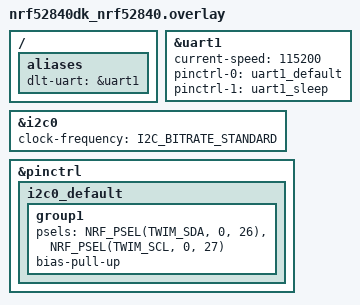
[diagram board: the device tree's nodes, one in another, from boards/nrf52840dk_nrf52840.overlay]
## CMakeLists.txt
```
# SPDX-License-Identifier: Apache-2.0

cmake_minimum_required(VERSION 3.20.0)
find_package(Zephyr REQUIRED HINTS $ENV{ZEPHYR_BASE})
project(base)

list(APPEND CMAKE_MODULE_PATH ${ZEPHYR_BASE}/modules/nanopb)
include(nanopb)

zephyr_nanopb_sources(app ${CMAKE_CURRENT_SOURCE_DIR}/../../../shared/phaethon.proto)

FILE(GLOB app_sources src/*.c)
FILE(GLOB lib_sources ../../lib/*.c)
target_sources(app PRIVATE ${app_sources} ${lib_sources})
target_include_directories(app PRIVATE ../../include)
```

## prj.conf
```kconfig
# GPIO Drivers
CONFIG_GPIO=y

# Shell Drivers
CONFIG_SHELL=y
CONFIG_SHELL_LOG_BACKEND=y
CONFIG_SHELL_ASYNC_API=y
CONFIG_SHELL_BACKEND_RTT=y

# Log Drivers
CONFIG_LOG=y
CONFIG_LOG_SPEED=y
CONFIG_LOG_CMDS=y
CONFIG_LOG_RUNTIME_FILTERING=y
CONFIG_LOG_BUFFER_SIZE=2048
CONFIG_LOG_PRINTK=y

# UART Drivers (DMA-based)
CONFIG_SERIAL=y
CONFIG_UART_ASYNC_API=y
CONFIG_UART_1_ASYNC=y

# Bluetooth
CONFIG_BT=y
CONFIG_BT_OBSERVER=y
CONFIG_BT_PERIPHERAL=y
CONFIG_BT_ZEPHYR_NUS=y
#CONFIG_BT_EXT_ADV=y
CONFIG_BT_FILTER_ACCEPT_LIST=y
CONFIG_BT_SHELL=y

# L2CAP SDU/PDU TX MTU
CONFIG_BT_BUF_ACL_TX_SIZE=251
CONFIG_BT_BUF_ACL_RX_SIZE=251
CONFIG_BT_L2CAP_TX_MTU=247

CONFIG_CBPRINTF_FP_SUPPORT=y

CONFIG_NANOPB=y

# FLYNN GPS i2C CONF
CONFIG_I2C=y
```

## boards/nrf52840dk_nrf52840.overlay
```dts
/ {
	aliases {
		dlt-uart = &uart1;
	};
};

&uart1 {
	status = "okay";
	current-speed = <115200>;
	pinctrl-0 = <&uart1_default>;
	pinctrl-1 = <&uart1_sleep>;
	pinctrl-names = "default", "sleep";
};

&i2c0 {
    clock-frequency = <I2C_BITRATE_STANDARD>;
};

&pinctrl {
    i2c0_default: i2c0_default {
		group1 {
			psels = <NRF_PSEL(TWIM_SDA, 0, 26)>,
				<NRF_PSEL(TWIM_SCL, 0, 27)>;
            bias-pull-up;
		};
	};
};
```

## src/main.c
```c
#include "zephyr/logging/log_core.h"
#include <math.h>
#include <zephyr/kernel.h>
#include <zephyr/drivers/gpio.h>
#include <zephyr/drivers/uart.h>
#include <zephyr/logging/log.h>
#include <pb_encode.h>
#include <pb_decode.h>

#ifdef CONFIG_SHELL_BACKEND_RTT
#include <zephyr/shell/shell_rtt.h>
#else
#include <zephyr/shell/shell.h>
#endif

#include "dlt_api.h"
#include "dlt_endpoints.h"
#include "base_bt.h"
#include "base_gps.h"
#include "phaethon.pb.h"

LOG_MODULE_REGISTER(base_main, LOG_LEVEL_INF);

#define PI 3.14159265358979323846f

/* Filter window for compass */
#define BEARING_FILTER_APERTURE  30.f

// Convert degrees to radians
static inline float degrees_to_radians(float degrees)
{
    return degrees * PI / 180.0f;
}

// Convert radians to degrees
static inline float radians_to_degrees(float radians)
{
    return radians * 180.0f / PI;
}

// Calculate the bearing between two points using the rhumb line technique
static float calculate_rhumb_line_bearing(float lat1, float lon1, float lat2,
                                          float lon2)
{
    
    /* Precalculate repeated values */
    const static float PI_ON_4 = PI / 4.0f;
    const static float TWO_PI = 2.0f * PI;
    
    // Convert latitudes and longitudes from degrees to radians
    float phi1 = degrees_to_radians(lat1);
    float phi2 = degrees_to_radians(lat2);
    float lambda1 = degrees_to_radians(lon1);
    float lambda2 = degrees_to_radians(lon2);

    // Calculate the projected latitude difference (Δψ)
    float delta_psi = logf(tanf(PI_ON_4 + phi2 / 2.0f) / tanf(PI_ON_4 + phi1 / 2.0f));

    // Calculate the difference in longitudes (Δλ)
    float delta_lambda = lambda2 - lambda1;

    // Adjust the difference in longitudes (Δλ) if necessary
    if (fabsf(delta_lambda) > PI) {
        if (delta_lambda > 0) {
            delta_lambda = -(TWO_PI - delta_lambda);
        } else {
            delta_lambda = TWO_PI + delta_lambda;
        }
    }

    // Calculate the bearing (brng)
    float bearing = atan2f(delta_lambda, delta_psi);

    // Convert the bearing from radians to degrees
    bearing = radians_to_degrees(bearing);

    // Normalize the bearing to be within the range [0, 360) degrees
    if (bearing < 0) {
        bearing += 360.0f;
    }

    return bearing;
}

// Check if the calculated bearing is within 30 degrees of the reference bearing
static bool is_within_bearing(float calculated_bearing, float reference_bearing) {
    float difference = fabsf(calculated_bearing - reference_bearing);

    // Adjust the difference to be the smallest angle between the bearings
    if (difference > 180.0f) {
        difference = 360.0f - difference;
    }

    // Return true if the difference is within 30 degrees
    return difference <= BEARING_FILTER_APERTURE;
}

int main(void)
{
    k_tid_t device_tid = k_current_get();
    dlt_interface_init(2);
    dlt_device_register(device_tid);

    /* Connect to the Thingy52 */
    LOG_INF("Connecting to Thingy52");
#ifdef CONFIG_SHELL_BACKEND_RTT
    shell_execute_cmd(shell_backend_rtt_get_ptr(), "blecon -s c8:91:07:19:03:58");
#else
    shell_execute_cmd(shell_backend_uart_get_ptr(), "blecon -s c8:91:07:19:03:58");
#endif

    uint8_t rx_data[DLT_MAX_DATA_LEN] = {0};
    uint8_t tx_buf[DLT_MAX_DATA_LEN] = {0};
    uint8_t resp_len = 0;
    uint8_t msg_type = 0;

    wsu_data_packet wsu; 
    bool wsu_conn = false;

    gps_base_data gps;
    gps.good_data = false;

    while (true) {

        /* Check the PI UART Link for data */
        resp_len = dlt_read(PI_UART, &msg_type, rx_data, DLT_MAX_DATA_LEN,
                            K_NO_WAIT);
        if (resp_len) {

            /* Decode message */
            bool status;

            /* Allocate space for the decoded message. */
            ADSBData message = ADSBData_init_zero;

            /* Create a stream that reads from the buffer. */
            pb_istream_t stream = pb_istream_from_buffer(rx_data, resp_len);

            /* Now we are ready to decode the message. */
            status = pb_decode(&stream, ADSBData_fields, &message);

            /* Check for errors */
            if (status) {
                /* Print the data contained in the message. */
                LOG_INF("Got packet for hex: %s", (char *)message.hex);
                // LOG_INF("flight: %s", message.flight);
                // LOG_INF("lat: %f", (double)message.lat);
                // LOG_INF("lon: %f", (double)message.lon);
                // LOG_INF("alt: %d", message.altitude);
                // LOG_INF("speed: %d", message.speed);
                // LOG_INF("track: %d", message.track);
            } else {
                LOG_ERR("Decoding failed: %s\n", PB_GET_ERROR(&stream));
            }

            /* GPS not bad */
            if (gps.good_data) {
                /* Filter the message */
                float rhumb_bearing = calculate_rhumb_line_bearing(gps.latitude,
                                                                gps.longitude,
                                                                message.lat,
                                                                message.lon);

                bool allow = is_within_bearing(rhumb_bearing, wsu.yaw);
                if (allow && wsu_conn) {
                    /* Forward message */
                    LOG_INF("Forwarding packet to M5.");
                    dlt_request(M5_NUS, tx_buf, rx_data, resp_len, true);
                } else {
                    LOG_INF("Ignoring packet. Not in heading.");
                }
            }
        }

        /* Check IMU data */
        if (!base_bt_wsu_data_recv(&wsu, K_NO_WAIT)) {
            /* Print the packet */
            // LOG_INF("p %f, r %f, y %f", (double)wsu.pitch,
            //         (double)wsu.roll, (double)wsu.yaw);
            LOG_INF("Yaw: %.02f", (double)wsu.yaw);
            wsu_conn = true;
        }

        /* Check GPS data */
        if (!base_gps_i2c_data_recv(&gps, K_NO_WAIT)) {
                if (gps.good_data) {
                    LOG_INF("lat: %f, lon %f", (double)gps.latitude, (double)gps.longitude);
                } else {
                    LOG_INF("GPS data is bad.");
                }
        }

        k_sleep(K_MSEC(3));
    }

    return 0;
}
```

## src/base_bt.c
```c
#include "zephyr/bluetooth/addr.h"
#include "zephyr/bluetooth/gap.h"
#include <zephyr/bluetooth/bluetooth.h>
#include <zephyr/kernel.h>
#include <zephyr/logging/log.h>

#include "base_bt.h"

LOG_MODULE_REGISTER(base_bt_module, LOG_LEVEL_ERR);

/* Thread parameters */
#define T_BASE_BT_STACKSIZE 1024
#define T_BASE_BT_PRIORITY  7

/* BASE BT State Machine States */
#define BASE_BT_IDLE_STATE      0
#define BASE_BT_SCANNING_STATE  1
#define BASE_BT_CONNECTED_STATE 2

/* Indexes into bt_data::data */
#define WSU_BT_DATA_MAJOR_START_IDX 20 // EXT implementation
#define WSU_BT_DATA_SEQ_START_IDX   10 
#define WSU_BT_DATA_PITCH_START_IDX 12 
#define WSU_BT_DATA_ROLL_START_IDX  16
#define WSU_BT_DATA_YAW_START_IDX   20

/* Define the message queue BT state machine commands */
K_MSGQ_DEFINE(base_bt_cmdq, sizeof(base_bt_cmd_t), 2, 1);

/* Define the message queue for passing WSU data */
K_MSGQ_DEFINE(wsu_dataq, sizeof(wsu_data_packet), 10, 1);

/* BASE BT State variable */
static uint8_t base_bt_state = BASE_BT_IDLE_STATE;

/* Rate limiting variables for HCI data forwarding */
uint64_t last_device_tx[4] = {0};

/* Send a cmd via the cmd queue */
extern void base_bt_cmd_send(base_bt_cmd_t *cmd, k_timeout_t timeout)
{
    k_msgq_put(&base_bt_cmdq, cmd, timeout);
}

/* Receive a message from the cmd queue */
static inline int base_bt_cmd_recv(base_bt_cmd_t *cmd, k_timeout_t timeout)
{
    return k_msgq_get(&base_bt_cmdq, cmd, timeout);
}

/* Send a cmd via the cmd queue */
static inline void base_bt_wsu_data_send(wsu_data_packet *pkt, k_timeout_t timeout)
{
    k_msgq_put(&wsu_dataq, pkt, timeout);
}

/* Receive a message from the cmd queue */
extern int base_bt_wsu_data_recv(wsu_data_packet *pkt, k_timeout_t timeout)
{
    return k_msgq_get(&wsu_dataq, pkt, timeout);
}

/* Initialise Bluetooth */
static inline bool base_bt_init(void)
{
    int err = bt_enable(NULL);
    if (err) {
        LOG_ERR("Bluetooth init failed (err %d)\n", err);
        return false;
    }
    return true;
}


static bool conn_data_cb(struct bt_data *data, void *user_data)
{
    /* Ignore non-manufacturer data segments */
    if (data->type != BT_DATA_MANUFACTURER_DATA) {
        /* Move to the next segment */
        return true;
    }

    /* Type-pun the packet value */
    union {
        uint32_t  u;
        float     f;
    } packet;

    #ifdef CONFIG_BT_EXT_ADV
    packet.u = 0;
    packet.u |= data->data[WSU_BT_DATA_MAJOR_START_IDX + 3];
    packet.u |= (((uint32_t)data->data[WSU_BT_DATA_MAJOR_START_IDX + 2]) << 8);
    packet.u |= (((uint32_t)data->data[WSU_BT_DATA_MAJOR_START_IDX + 1]) << 16);
    packet.u |= (((uint32_t)data->data[WSU_BT_DATA_MAJOR_START_IDX]) << 24);

    wsu_data_packet *p = user_data;
    p->type = data->data[WSU_BT_DATA_MAJOR_START_IDX - 1];
    p->value = packet.f;

    /* Print the packet */
    if (p->type == 0x01) {
        LOG_INF("pitch: %f\n", (double)p->value);
    } else if (p->type == 0x02) {
        LOG_INF("roll: %f\n", (double)p->value);
    } else if (p->type == 0x03) {
        LOG_INF("yaw: %f\n", (double)p->value);
    }
    #else
    wsu_data_packet *p = user_data;

    /* Get sequence */
    p->sequence = (((uint16_t)data->data[WSU_BT_DATA_SEQ_START_IDX]) << 8);
    p->sequence |= data->data[WSU_BT_DATA_SEQ_START_IDX + 1];

    /* Get pitch */
    packet.u = 0;
    packet.u |= data->data[WSU_BT_DATA_PITCH_START_IDX + 3];
    packet.u |= (((uint32_t)data->data[WSU_BT_DATA_PITCH_START_IDX + 2]) << 8);
    packet.u |= (((uint32_t)data->data[WSU_BT_DATA_PITCH_START_IDX + 1]) << 16);
    packet.u |= (((uint32_t)data->data[WSU_BT_DATA_PITCH_START_IDX]) << 24);
    p->pitch = packet.f;

    /* Get roll */
    packet.u = 0;
    packet.u |= data->data[WSU_BT_DATA_ROLL_START_IDX + 3];
    packet.u |= (((uint32_t)data->data[WSU_BT_DATA_ROLL_START_IDX + 2]) << 8);
    packet.u |= (((uint32_t)data->data[WSU_BT_DATA_ROLL_START_IDX + 1]) << 16);
    packet.u |= (((uint32_t)data->data[WSU_BT_DATA_ROLL_START_IDX]) << 24);
    p->roll = packet.f;

    /* Get yaw */
    packet.u = 0;
    packet.u |= data->data[WSU_BT_DATA_YAW_START_IDX + 3];
    packet.u |= (((uint32_t)data->data[WSU_BT_DATA_YAW_START_IDX + 2]) << 8);
    packet.u |= (((uint32_t)data->data[WSU_BT_DATA_YAW_START_IDX + 1]) << 16);
    packet.u |= (((uint32_t)data->data[WSU_BT_DATA_YAW_START_IDX]) << 24);
    p->yaw = packet.f;

    /* Print the packet */
    LOG_INF("seq %" PRIu16 " p %f, r %f, y %f\n", p->sequence, (double)p->pitch,
            (double)p->roll, (double)p->yaw);
    #endif

    /* Stop data processing */
    return false;
}

/* Scan callback function for handling generic scanning */
static void ble_scan_recv(const bt_addr_le_t *addr, int8_t rssi, uint8_t type,
                          struct net_buf_simple *ad)
{
    if (base_bt_state != BASE_BT_SCANNING_STATE) {
        return;
    }
    char addr_str[BT_ADDR_LE_STR_LEN];
    bt_addr_le_to_str(addr, addr_str, sizeof(addr_str));
    printk("Device found: %s (RSSI %d), type %u, AD data len %u\n", addr_str,
           rssi, type, ad->len);
}

/* Scan callback function for handling WSU beacon connections */
static void ble_conn_recv(const bt_addr_le_t *addr, int8_t rssi, uint8_t type,
                          struct net_buf_simple *ad)
{
    if (base_bt_state != BASE_BT_CONNECTED_STATE) {
        return;
    }

    char addr_str[BT_ADDR_LE_STR_LEN];
    bt_addr_le_to_str(addr, addr_str, sizeof(addr_str));

    /* Parse the WSU data */
    wsu_data_packet packet;
    bt_data_parse(ad, conn_data_cb, &packet);
    
    /* Send it to the main thread */
    base_bt_wsu_data_send(&packet, K_MSEC(1));
    
}

/* State machine which bakes the Bluetooth API cmds into transition logic. */
void base_bt_thread(void)
{
    /* Initialise the module */
    // if (!base_bt_init()) {
    //     LOG_ERR("BASE BT init failed.");
    //     return;
    // }

    /* Set the scan parameters */
    struct bt_le_scan_param scan_param = {
        .type = BT_LE_SCAN_TYPE_PASSIVE,
        .options = BT_LE_SCAN_OPT_NONE,
        .interval = BT_GAP_SCAN_FAST_INTERVAL_MIN,
        .window = BT_GAP_SCAN_FAST_WINDOW
    };

    while (1) {
        base_bt_cmd_t cmd;
        int err;
        switch (base_bt_state) {
        case BASE_BT_IDLE_STATE:
            /* Do nothing while waiting for a command */
            base_bt_cmd_recv(&cmd, K_FOREVER);

            /* Process the command */
            if (cmd.cmd_type == BASE_BT_SCAN_START && !cmd.filter) {
                /* Start the scan */
                scan_param.options = BT_LE_SCAN_OPT_FILTER_DUPLICATE;
                err = bt_le_scan_start(&scan_param, ble_scan_recv);
                if (err) {
                    LOG_ERR("Start SCAN failed (err %d)\n", err);
                    break;
                }

                LOG_INF("Transitioning to scanning state.");
                base_bt_state = BASE_BT_SCANNING_STATE;

            } else if (cmd.cmd_type == BASE_BT_SCAN_START && cmd.filter) {
                /* Setup the filter */
                bt_le_filter_accept_list_add(&cmd.addr);
                scan_param.options |= BT_LE_SCAN_OPT_FILTER_ACCEPT_LIST;

                /* Start the scan */
                err = bt_le_scan_start(&scan_param, ble_scan_recv);
                if (err) {
                    LOG_ERR("Start SCAN failed (err %d)\n", err);
                    break;
                }

                LOG_INF("Transitioning to scanning state (filtered).");
                base_bt_state = BASE_BT_SCANNING_STATE;

            } else if (cmd.cmd_type == BASE_BT_CONN_START) {
                /* Setup the filter */
                bt_le_filter_accept_list_add(&cmd.addr);
                scan_param.options |= BT_LE_SCAN_OPT_FILTER_ACCEPT_LIST;

                /* Start the scan */
                err = bt_le_scan_start(&scan_param, ble_conn_recv);
                if (err) {
                    LOG_ERR("Start CONN failed (err %d)\n", err);
                    break;
                }

                LOG_INF("Transitioning to connected state.");
                base_bt_state = BASE_BT_CONNECTED_STATE;

            } else {
                LOG_ERR("Invalid transition cmd from IDLE state.");
            }
            break;

        case BASE_BT_SCANNING_STATE:
            /* Do nothing while waiting for a command */
            base_bt_cmd_recv(&cmd, K_FOREVER);

            /* Only accept stop commands in the SCAN state*/
            if (cmd.cmd_type == BASE_BT_SCAN_STOP && !cmd.filter) {
                /* Stop scanning */
                err = bt_le_scan_stop();
                if (err) {
                    LOG_ERR("Stop SCAN failed (err %d)\n", err);
                    break;
                }

                /* Reset the filter list */
                bt_le_filter_accept_list_clear();

                LOG_INF("Transitioning to IDLE state.");
                base_bt_state = BASE_BT_IDLE_STATE;

            } else if (cmd.cmd_type == BASE_BT_SCAN_STOP && cmd.filter) {
                /* Stop the scan */
                err = bt_le_scan_stop();
                if (err) {
                    LOG_ERR("Stop SCAN failed (err %d)\n", err);
                    break;
                }

                /* Remove the address from the filter list */
                bt_le_filter_accept_list_remove(&cmd.addr);
                scan_param.options |= BT_LE_SCAN_OPT_FILTER_ACCEPT_LIST;

                /* Restart the scan */
                err = bt_le_scan_start(&scan_param, ble_scan_recv);
                if (err) {
                    LOG_ERR("Start SCAN failed (err %d)\n", err);
                    break;
                }

            } else if (cmd.cmd_type == BASE_BT_SCAN_START && cmd.filter) {
                /* Stop the scan */
                err = bt_le_scan_stop();
                if (err) {
                    LOG_ERR("Stop SCAN failed (err %d)\n", err);
                    break;
                }

                /* Add the new filter */
                bt_le_filter_accept_list_add(&cmd.addr);
                scan_param.options |= BT_LE_SCAN_OPT_FILTER_ACCEPT_LIST;

                /* Restart the scan */
                err = bt_le_scan_start(&scan_param, ble_scan_recv);
                if (err) {
                    LOG_ERR("Start SCAN failed (err %d)\n", err);
                    break;
                }

            } else if (cmd.cmd_type == BASE_BT_SCAN_START && !cmd.filter) {
                /* Stop the scan */
                err = bt_le_scan_stop();
                if (err) {
                    LOG_ERR("Stop SCAN failed (err %d)\n", err);
                    break;
                }

                /* Reset filter list and disable filtering */
                bt_le_filter_accept_list_clear();
                scan_param.options = BT_LE_SCAN_OPT_FILTER_DUPLICATE;
                ;

                /* Restart the scan */
                err = bt_le_scan_start(&scan_param, ble_scan_recv);
                if (err) {
                    LOG_ERR("Start SCAN failed (err %d)\n", err);
                    break;
                }

            } else {
                LOG_ERR("Invalid transition cmd from SCAN state.");
            }

            break;

        case BASE_BT_CONNECTED_STATE:
            /* Wait for a command */
            base_bt_cmd_recv(&cmd, K_FOREVER);

            if (cmd.cmd_type == BASE_BT_CONN_STOP) {

                /* Stop scanning and transition back to IDLE */
                err = bt_le_scan_stop();
                if (err) {
                    LOG_ERR("Stop SCAN failed (err %d)\n", err);
                    break;
                }

                /* Reset the filter list */
                bt_le_filter_accept_list_clear();

                LOG_INF("Transitioning to IDLE state.");
                base_bt_state = BASE_BT_IDLE_STATE;

            } else {
                LOG_ERR("Invalid transition cmd from CONN state.");
            }

            break;

        default:
            /* Shouldn't get here */
            base_bt_state = BASE_BT_IDLE_STATE;
            break;
        }
    }
}

K_THREAD_DEFINE(base_bt, T_BASE_BT_STACKSIZE, base_bt_thread, NULL, NULL, NULL,
                T_BASE_BT_PRIORITY, 0, 0);
```

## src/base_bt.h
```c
#ifndef BASE_BT_H_
#define BASE_BT_H_

#include <zephyr/bluetooth/addr.h>
#include <zephyr/kernel.h>

/* Command IDs for base_bt cmds */
#define BASE_BT_SCAN_START 0x00U
#define BASE_BT_SCAN_STOP  0x01U
#define BASE_BT_CONN_START 0x02U
#define BASE_BT_CONN_STOP  0x03U

#ifdef CONFIG_BT_EXT_ADV
typedef struct wsu_data_packet {
    uint8_t type;
    float value;
} wsu_data_packet;
#else
typedef struct wsu_data_packet {
    uint16_t sequence;
    float pitch;
    float roll;
    float yaw;
} wsu_data_packet;
#endif

/* base_bt_cmd_t represents commands to the ahu_bt state machine */
typedef struct {
    uint8_t cmd_type;
    bool filter;
    bt_addr_le_t addr;
} base_bt_cmd_t;

/* Prototypes */
extern void base_bt_cmd_send(base_bt_cmd_t *cmd, k_timeout_t timeout);
extern int base_bt_wsu_data_recv(wsu_data_packet *pkt, k_timeout_t timeout);

#endif
```

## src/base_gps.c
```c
/*
 * flynnmkelly
 */

#include <zephyr/kernel.h>
#include <zephyr/device.h>
#include <zephyr/drivers/uart.h>
#include <zephyr/drivers/i2c.h>
#include <zephyr/logging/log.h>
#include <string.h>
#include <stdio.h>
#include <stdlib.h>

#include "base_gps.h"

LOG_MODULE_REGISTER(gps_module, LOG_LEVEL_ERR);

/* Zephyr Handlers */
#define UART_DEVICE_NODE DT_CHOSEN(zephyr_shell_uart)
#define I2C_DEVICE_NODE DT_NODELABEL(i2c0) 

/* Thread Parameters */
#define T_BASE_GPS_STACKSIZE 2048 
#define T_BASE_GPS_PRIORITY  7

/* GPS i2C */
#define GPS_I2C_ADDR 0x10 // 7-bit unshifted default I2C Address
#define MAX_GPS_PACKET_SIZE 255
static uint8_t gps_data[MAX_GPS_PACKET_SIZE];

/* Config */
static const struct device *const uart_dev = DEVICE_DT_GET(UART_DEVICE_NODE);
static const struct device *i2c_dev;
uint32_t i2c_cfg = I2C_SPEED_SET(I2C_SPEED_STANDARD) | I2C_MODE_CONTROLLER;

/* NMEA Parsing */
#define PMTK_FULL_COLD_START "$PMTK103*30<CR><LF>"  
#define MAX_NMEA_SENTENCE_SIZE 80
uint8_t gnrmc_sentence[MAX_NMEA_SENTENCE_SIZE];
gps_base_data gps_data_struct;

/* Define the message queue for comms with control thread */
K_MSGQ_DEFINE(gps_base_msgq, sizeof(gps_base_data), 10, 4);

/* *** FUNCTIONS TO BE CALLED IN main.c/CONTROsL THREAD *** */

/* Receive a gps data struct from the queue */
int base_gps_i2c_data_recv(gps_base_data *gps_struct, k_timeout_t timeout) {
    
    return k_msgq_get(&gps_base_msgq, gps_struct, timeout);

}

/* *** FUNCTIONS WHICH RUN IN THREAD *** */
bool gps_init(const struct device *dev) {
    if (!device_is_ready(dev)) {
        LOG_ERR("I2C device is not ready");
        return false;
    }

	/* Verify i2c_configure() */
	if (i2c_configure(dev, i2c_cfg)) {
		LOG_ERR("I2C config failed\n");
		return false;
	}

    uint8_t dummy = 0x00;
    int ret = i2c_write(dev, &dummy, 1, GPS_I2C_ADDR);
    if (ret) {
        LOG_ERR("GPS module not responding at address 0x%02X", GPS_I2C_ADDR);
        return false;
    }
    LOG_INF("GPS module found at address 0x%02X!", GPS_I2C_ADDR);
    
	k_sleep(K_MSEC(10));

	// Attempt to read a byte to ensure the device is responding
    uint8_t response;
    ret = i2c_read(dev, &response, 1, GPS_I2C_ADDR);
    if (ret) {
        LOG_ERR("Failed to read from GPS module at address 0x%02X", GPS_I2C_ADDR);
        return false;
    }

    LOG_INF("GPS module found and responding at address 0x%02X!", GPS_I2C_ADDR);
    return true;
}

static int send_full_cold_start_command(const struct device *i2c_dev) {
    const char *cmd = PMTK_FULL_COLD_START;
    size_t len = strlen(cmd);
    int ret = i2c_write(i2c_dev, cmd, len, GPS_I2C_ADDR);
    if (ret != 0) {
        LOG_ERR("Failed to send full cold start command: %d", ret);
    } else {
        LOG_INF("Full cold start command sent successfully.");
    }
    return ret;
}

/**
 * This function reads an NMEA packet from the GPS module via I2C communication.
 * It reads the packet in chunks of maximum buffer size and appends them to the provided buffer.
 */
static int read_nmea_packet(uint8_t *buffer, size_t size)
{
    int ret;
    size_t total_read = 0;
    const size_t read_size = 255;  // Max buffer size to read at once

    while (total_read < size) {
        ret = i2c_burst_read(i2c_dev, GPS_I2C_ADDR, 0x00, buffer + total_read, read_size);
        if (ret) {
            LOG_ERR("I2C read failed with error %d", ret);
            return ret;
        }
        total_read += read_size;
        k_sleep(K_MSEC(2)); // Short sleep to allow buffer refresh
    }

    buffer[size - 1] = '\0';  // Ensure null-termination

    return 0;
}


/* Reads and Logs NMEA Packets */
static void check_gps_data(void) {
    int ret = read_nmea_packet(gps_data, MAX_GPS_PACKET_SIZE);
    if (ret == 0) {
        LOG_INF("GPS data processed successfully.");
        // Here you can add further processing or handling of the GPS data if needed
        
        // OUTPUT RAW VALUES from TitanX1 Buffer
        //printk("GPS Data: %s\n", gps_data);

    } else {
        LOG_ERR("Failed to read GPS data.");
    }
}

/*
 * Function to find and log the GNRMC sentence from the GPS data buffer
 * and store it in a global buffer for further processing.
 */
static void extract_gnrmc(const uint8_t *buffer) {
    // Pointer to the start of the GNRMC sentence within the buffer
    const char *gnrmc_start = strstr((const char *)buffer, "$GNRMC");
    if (gnrmc_start != NULL) {
        // Find the end of the GNRMC sentence, marked by the newline character
        const char *gnrmc_end = strchr(gnrmc_start, '\n');
        if (gnrmc_end != NULL) {
            // Calculate the length of the GNRMC sentence
            size_t gnrmc_length = gnrmc_end - gnrmc_start;
            if (gnrmc_length > 1 && gnrmc_length < MAX_NMEA_SENTENCE_SIZE) {
                // Copy the sentence into the global buffer, ensuring not to overflow
                strncpy((char *)gnrmc_sentence, gnrmc_start, gnrmc_length);
                gnrmc_sentence[gnrmc_length] = '\0';  // Null-terminate the string

                // Log the GNRMC sentence
                LOG_INF("GNRMC Sentence stored: %s", gnrmc_sentence);

            } else {
                LOG_ERR("GNRMC sentence length is too long or too short");
            }
        } else {
            LOG_ERR("GNRMC sentence not properly terminated");
        }
    } else {
        LOG_ERR("GNRMC sentence not found in buffer");
    }
}

/*
 * Function to convert latitude and longitude from NMEA format (ddmm.mmmm) to decimal degrees
 */
static float nmea_to_decimal(float nmea_value, char direction) {
    int degrees = (int)(nmea_value / 100);
    float minutes = nmea_value - (degrees * 100);
    float decimal_degrees = degrees + (minutes / 60);
    if (direction == 'S' || direction == 'W') {  // For Southern Hemisphere or Western Hemisphere
        decimal_degrees = -decimal_degrees;
    }
    return decimal_degrees;
}

/*
 * Function to parse GNRMC sentence and update the global GPS data struct
 * $GNRMC,234042.000,A,2729.7905,S,15259.7095,E,1.00,262.90,120524,,,A*64
 */
void parse_gnrmc(const uint8_t *gnrmc_sentence) {
    char status = 'V', lat_dir = 'S', long_dir = 'E';
    float latitude = 0.0, longitude = 0.0;
    char *token;
    int field_count = 0;

    // Create a copy of the sentence for strtok manipulation
    char sentence_copy[100];
    strncpy(sentence_copy, (const char *)gnrmc_sentence, 99);
    sentence_copy[99] = '\0';

    token = strtok(sentence_copy, ",");

    while (token != NULL) {
        field_count++;
        switch (field_count) {
            case 3:  // Status
                status = token[0];
                break;
            case 4:  // Latitude
                if (token[0] != '\0') latitude = atof(token);
                break;
            case 5:  // Latitude direction
                if (token[0] != '\0') lat_dir = token[0];
                break;
            case 6:  // Longitude
                if (token[0] != '\0') longitude = atof(token);
                break;
            case 7:  // Longitude direction
                if (token[0] != '\0') long_dir = token[0];
                break;
        }
        token = strtok(NULL, ",");
    }

    // Set the struct fields
    gps_data_struct.good_data = (status == 'A'); // works
    gps_data_struct.latitude = nmea_to_decimal(latitude, lat_dir);
    gps_data_struct.longitude = nmea_to_decimal(longitude, long_dir);
}

/* Thread which sends relevant GPS data to main */
void base_gps_thread(void)
{

    if (!device_is_ready(uart_dev)) {
        LOG_ERR("UART device not found!\n");
        return;
    }

    i2c_dev = DEVICE_DT_GET(I2C_DEVICE_NODE);
    if (!gps_init(i2c_dev)) {
        LOG_ERR("GPS initialization failed!\n");
        return;
    }
	k_sleep(K_MSEC(10));

    // Sending the full cold start command
    if (send_full_cold_start_command(i2c_dev) != 0) {
        LOG_ERR("Failed to reset GPS module.\n");
    } else { // wsa successful
        //printk("GPS module reset successfully.\n");
    }
    k_sleep(K_MSEC(10));

    while (1) {
        
		// poll evert 500mss
        check_gps_data();
        extract_gnrmc(gps_data);

        // parse data into struct
        parse_gnrmc(gnrmc_sentence);

        // send data via msgqueue
        k_msgq_put(&gps_base_msgq, &gps_data_struct, K_MSEC(3000));

        // delay for relevant time (let titanX1 buffer fill)
        k_sleep(K_MSEC(2000));

    }
}


K_THREAD_DEFINE(base_gps, T_BASE_GPS_STACKSIZE, base_gps_thread, NULL, NULL,
                NULL, T_BASE_GPS_PRIORITY, 0, 0);
```

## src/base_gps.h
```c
#ifndef BASE_GPS_H_
#define BASE_GPS_H_

#include <zephyr/kernel.h>

/* Struct to be sent over thread */
typedef struct {
    bool good_data; // if status flag is A = true, if V = false
    float latitude;  // decimal degrees
    float longitude;
} gps_base_data;

/* Prototypes */
int base_gps_i2c_data_recv(gps_base_data *gps_struct, k_timeout_t timeout);

#endif
```

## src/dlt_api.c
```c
#include <zephyr/kernel.h>
#include <zephyr/logging/log.h>

#include "dlt_api.h"

LOG_MODULE_REGISTER(dlt_api, LOG_LEVEL_INF);

/* Mailbox array for endpoints */
struct k_mbox eps[DLT_MAX_ENDPOINTS];
static k_tid_t link_tids[DLT_MAX_ENDPOINTS];

static k_tid_t device_tid;

/* Initialise the interface */
extern bool dlt_interface_init(uint8_t num_endpoints)
{
    if (num_endpoints > DLT_MAX_ENDPOINTS) {
        LOG_ERR("Too many endpoints.");
        return false;
    }
 
    /* Initialise the mailboxes */
    for (int i = 0; i < num_endpoints; i++) {
        k_mbox_init(&eps[i]);
    }

    return true;
}

extern void dlt_device_register(k_tid_t dev_tid)
{
    device_tid =  dev_tid;
}

extern void dlt_link_register(uint8_t ep, k_tid_t link_tid)
{
    link_tids[ep] = link_tid;
}

/* Create a packet and return its length */
static inline uint8_t dlt_generate_packet(uint8_t *packet, uint8_t msg_type,
                                          uint8_t *data, uint8_t data_len)
{
    if (data_len + DLT_PROTOCOL_BYTES > DLT_MAX_PACKET_LEN) {
        LOG_ERR("Data is too large.");
        return 0;
    }

    packet[0] = DLT_PREAMBLE;
    packet[1] = msg_type;
    packet[2] = data_len;

    /* Copy data segment into packet */ 
    for (int i = 0; i < data_len; i++) {
        packet[i + DLT_PROTOCOL_BYTES] = data[i];
    }

    return data_len + DLT_PROTOCOL_BYTES;
}

/* Generic method for sending packets via mailbox */
static inline void dlt_send(uint8_t ep, uint8_t *packet,
                            uint8_t packet_len, uint8_t msg_type,
                            k_tid_t send_tid, bool async)
{
    /* Create mailbox message */
    struct k_mbox_msg send_msg;
    send_msg.info = msg_type;
    send_msg.size = packet_len;
    send_msg.tx_data = packet;
    send_msg.tx_target_thread = send_tid;

    /* Send message asynchronously without validation */
    if (async) {
        LOG_INF("Sending async DLT message.");
        k_mbox_async_put(&eps[ep], &send_msg, NULL);
        return;
    }

    /* Send message synchronously and validate response */
    k_mbox_put(&eps[ep], &send_msg, K_FOREVER);

    if (send_msg.size < packet_len) {
        LOG_WRN("DLT message data dropped during transfer!");
        LOG_WRN("DLT receiver only had room for %d bytes", send_msg.info);
    }

}

extern void dlt_request(uint8_t ep, uint8_t *packet, uint8_t *data, uint8_t data_len, bool async)
{
    /* Create the DLT packet */
    uint8_t packet_len = dlt_generate_packet(packet, DLT_REQUEST_CODE,
                                             data, data_len);

    /* Submit the packet to the Link for transfer */
    dlt_send(ep, packet, packet_len, DLT_REQUEST_CODE, link_tids[ep], async);
}

extern void dlt_respond(uint8_t ep, uint8_t *packet, uint8_t *data, uint8_t data_len, bool async)
{
    /* Create the DLT packet */
    uint8_t packet_len = dlt_generate_packet(packet, DLT_RESPONSE_CODE,
                                             data, data_len);

    /* Submit the packet to the Link for transfer */
    dlt_send(ep, packet, packet_len, DLT_RESPONSE_CODE, link_tids[ep], async);
}

/* Submits the packet to the DLT interface for a Device to read */
extern void dlt_submit(uint8_t ep, uint8_t *packet, uint8_t packet_len,
                       bool async)
{
    uint8_t msg_type = packet[1];
    dlt_send(ep, packet, packet_len, msg_type, device_tid, async);
}

extern uint8_t dlt_read(uint8_t ep, uint8_t *msg_type, uint8_t *data,
                        uint8_t data_len, k_timeout_t timeout)
{
    struct k_mbox_msg recv_msg;
    recv_msg.size = 100;
    recv_msg.rx_source_thread = link_tids[ep];

    /* Wait to get message, but don't consume it */
    if (k_mbox_get(&eps[ep], &recv_msg, NULL, timeout)) {
        return 0;
    }

    /* Consume message and get its data */
    uint8_t rx_packet[DLT_MAX_PACKET_LEN] = {0};
    k_mbox_data_get(&recv_msg, &rx_packet);

    if (recv_msg.size > DLT_MAX_PACKET_LEN || 
            (recv_msg.size - DLT_PROTOCOL_BYTES) > data_len) {
        LOG_ERR("Message receive error. Data segment is too big.");
        return 0;
    }

    /* Get the message type */
    *msg_type = recv_msg.info;

    /* Copy the packet's data segment into data */
    for (int i = 0; i < recv_msg.size - DLT_PROTOCOL_BYTES; i++) {
        data[i] = rx_packet[i + DLT_PROTOCOL_BYTES];
    }
    return recv_msg.size - DLT_PROTOCOL_BYTES;
}

/* Polling function for Links to check if packets are available */
extern uint8_t dlt_poll(uint8_t ep, uint8_t *packet, uint8_t packet_len,
                        k_timeout_t timeout)
{
    struct k_mbox_msg recv_msg;
    recv_msg.size = 100;
    recv_msg.rx_source_thread = device_tid;

    /* Wait to get message, but don't consume it */
    if (k_mbox_get(&eps[ep], &recv_msg, NULL, timeout)) {
        return 0;
    }

    /* Consume message and get its data */
    k_mbox_data_get(&recv_msg, packet);

    if (recv_msg.size > DLT_MAX_PACKET_LEN || recv_msg.size > packet_len) {
        LOG_ERR("Message receive error. Packet is too big.");
        return 0;
    }

    return recv_msg.size;
}
```

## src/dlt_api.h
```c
/**
 * @file dlt_api.h
 *
 * @brief Device Link Transfer (DLT) API Header File
 *
 * This header file defines the interface for the Device Link Transfer (DLT) API.
 * DLT is a abstraction layer used for routing messages in a one-to-many fashion
 * from a Device to a Link, for transmission to a another device.
 *
 * In embedded systems applications, DLT enables developers to focus on
 * application code, rather than data passing primitives for required for 
 * message sharing. Users of the DLT protocol need only write peripheral
 * interfaces, then call the relevant DLT API functions to enable data reception
 * and transmission from separate threads.
 *
 * @note This header file should be included in projects that utilize the DLT API.
 *
 * @author Sam Kwort
 * @date 08/05/2024 
 */

#ifndef DLT_API_H_
#define DLT_API_H_

#include <zephyr/kernel.h>

/* DLT interface configuration */
#define DLT_MAX_PACKET_LEN 50 
#define DLT_PROTOCOL_BYTES 3  // don't change
#define DLT_MAX_DATA_LEN   DLT_MAX_PACKET_LEN - DLT_PROTOCOL_BYTES
#define DLT_MAX_ENDPOINTS 3

/* DLT Protocol Codes */
#define DLT_PREAMBLE 0x77
#define DLT_REQUEST_CODE 0x01
#define DLT_RESPONSE_CODE 0x02

/**
 * @brief Initializes the DLT interface with the specified number of endpoints.
 *
 * This function initializes the Device Link Transfer (DLT) interface with the
 * specified number of endpoints. Users should call this function once during
 * initialization, providing the number of endpoints to be supported.
 *
 * @param num_endpoints Number of endpoints to be supported.
 * @return true if initialization is successful, false otherwise.
 */
extern bool dlt_interface_init(uint8_t num_endpoints);

/**
 * @brief Registers the device thread with the DLT interface.
 *
 * This function registers the calling thread as a device with the DLT
 * interface. It should be called in the main thread of the device.
 *
 * @param dev_tid Thread ID of the device thread.
 */
extern void dlt_device_register(k_tid_t dev_tid);

/**
 * @brief Registers a link thread with the DLT interface.
 *
 * This function registers the calling thread as a link with the DLT interface.
 * It should be called in the thread associated with the link endpoint.
 *
 * @param ep Endpoint identifier for the link.
 * @param link_tid Thread ID of the link thread.
 */
extern void dlt_link_register(uint8_t ep, k_tid_t link_tid);

/**
 * @brief Sends a DLT request from a device to a link for data transfer.
 *
 * This function sends a DLT request from a device to a link for data transfer.
 *
 * @param ep Endpoint identifier for the link.
 * @param packet Pointer to a buffer used for storing and transferring the DLT encoded packet.
 * @param data Pointer to the data payload.
 * @param data_len Length of the data payload.
 * @param async If true, the transfer is asynchronous; otherwise, it is synchronous.
 */
extern void dlt_request(uint8_t ep, uint8_t *packet, uint8_t *data,
                        uint8_t data_len, bool async);

/**
 * @brief Sends a DLT response from a device to a link for data transfer..
 *
 * This function sends a DLT response from a device to a link for data transfer.
 *
 * @param ep Endpoint identifier for the link.
 * @param packet Pointer to a buffer used for storing and transferring the DLT encoded packet.
 * @param data Pointer to the data payload.
 * @param data_len Length of the data payload.
 * @param async If true, the transfer is asynchronous; otherwise, it is synchronous.
 */
extern void dlt_respond(uint8_t ep, uint8_t *packet, uint8_t *data,
                        uint8_t data_len, bool async);

/**
 * @brief Reads data from a link for a device.
 *
 * This function reads data from a link for a device.
 *
 * @param ep Endpoint identifier for the link.
 * @param msg_type Pointer to store the message type.
 * @param data Pointer to store the received data.
 * @param data_len Length of the buffer to store the received data.
 * @param timeout Timeout value for reading data.
 * @return Number of bytes read, or 0 if no data is available within the timeout.
 */
extern uint8_t dlt_read(uint8_t ep, uint8_t *msg_type, uint8_t *data,
                        uint8_t data_len, k_timeout_t timeout);

/**
 * @brief Submits a packet to be sent through a link.
 *
 * This function submits a packet through a link to the device.
 *
 * @param ep Endpoint identifier for the link.
 * @param packet Pointer to the packet to be sent.
 * @param packet_len Length of the packet to be sent.
 * @param async If true, the submission is asynchronous; otherwise, it is synchronous.
 */
extern void dlt_submit(uint8_t ep, uint8_t *packet, uint8_t packet_len,
                       bool async);

/**
 * @brief Polls for incoming packets on a link.
 *
 * This function polls for incoming packets on a link.
 *
 * @param ep Endpoint identifier for the link.
 * @param packet Pointer to store the received packet.
 * @param packet_len Length of the buffer to store the received packet.
 * @param timeout Timeout value for polling.
 * @return Number of bytes received, or 0 if no packet is available within the timeout.
 */
extern uint8_t dlt_poll(uint8_t ep, uint8_t *packet, uint8_t packet_len,
                        k_timeout_t timeout);

#endif // DLT_API_H_
```

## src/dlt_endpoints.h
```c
#ifndef DLT_ENDPOINTS_H_
#define DLT_ENDPOINTS_H_

#include <zephyr/kernel.h>

/* Set the number of endpoints */
#define DLT_NUM_ENDPOINTS 2 

/* Define your endpoints*/
enum dlt_endpoints {
    PI_UART = 0,
    M5_NUS = 1,
};

#endif // DLT_ENDPOINTS_H_
```

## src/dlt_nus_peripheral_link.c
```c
#include <zephyr/kernel.h>
#include <zephyr/device.h>
#include <zephyr/logging/log.h>
#include <zephyr/bluetooth/bluetooth.h>
#include <zephyr/bluetooth/services/nus.h>

#include "dlt_api.h"
#include "dlt_endpoints.h"

/* Thread parameters */
#define DLT_NUS_STACKSIZE 2048
#define DLT_NUS_PRIORITY  6

/* Bluetooth Device Parameters */
#define DEVICE_NAME		CONFIG_BT_DEVICE_NAME
#define DEVICE_NAME_LEN		(sizeof(DEVICE_NAME) - 1)

LOG_MODULE_REGISTER(dlt_nus_link, LOG_LEVEL_ERR);

static const struct bt_data ad[] = {
	BT_DATA_BYTES(BT_DATA_FLAGS, (BT_LE_AD_GENERAL | BT_LE_AD_NO_BREDR)),
	BT_DATA(BT_DATA_NAME_COMPLETE, DEVICE_NAME, DEVICE_NAME_LEN),
};

static const struct bt_data sd[] = {
	BT_DATA_BYTES(BT_DATA_UUID128_ALL, BT_UUID_NUS_SRV_VAL),
};

static void notif_enabled(bool enabled, void *ctx)
{
	ARG_UNUSED(ctx);

	LOG_INF("%s() - %s\n", __func__, (enabled ? "Enabled" : "Disabled"));
}

static void received(struct bt_conn *conn, const void *data, uint16_t len, void *ctx)
{
	char message[CONFIG_BT_L2CAP_TX_MTU + 1] = "";

	ARG_UNUSED(conn);
	ARG_UNUSED(ctx);

	memcpy(message, data, MIN(sizeof(message) - 1, len));
	LOG_INF("%s() - Len: %d, Message: %s\n", __func__, len, message);
}

struct bt_nus_cb nus_listener = {
	.notif_enabled = notif_enabled,
	.received = received,
};

/* Initialise the NUS Link */
static bool dlt_nus_peripheral_init()
{
	int err = bt_nus_cb_register(&nus_listener, NULL);
	if (err) {
		LOG_ERR("Failed to register NUS callback: %d\n", err);
		return false;
	}

    err = bt_enable(NULL);
	if (err) {
		LOG_ERR("Failed to enable bluetooth: %d\n", err);
		return false;
	}

	err = bt_le_adv_start(BT_LE_ADV_CONN, ad, ARRAY_SIZE(ad), sd, ARRAY_SIZE(sd));
	if (err) {
		LOG_ERR("Failed to start advertising: %d\n", err);
		return false;
	}

    return true;
}

/**
 * Thread function for DLT Communication.
 * 
 * @brief Periodically polls the DLT interface for packets to transmit and 
 *        forwards any received packets.
 */
void dlt_nus_peripheral_thread(void) {
    /* Initialise the UART peripheral and register Link with DLT driver */
    k_tid_t link_tid = k_current_get();
    dlt_nus_peripheral_init();
    dlt_link_register(M5_NUS, link_tid);

	LOG_INF("Initialization complete\n");
    int err = 0;

    uint8_t dlt_recv_buf[DLT_MAX_PACKET_LEN] = {0};

    /* Sleep to let the main thread setup DLT */
    k_sleep(K_MSEC(100));

	while (true) {
        /* Poll DLT Interface for packets to transmit */
        uint8_t msg_len = dlt_poll(M5_NUS, dlt_recv_buf, 50, K_MSEC(5));
        if (msg_len) {
            LOG_INF("DLT mail received.");

            /* Transmit the DLT packet via UART */
            LOG_INF("Transmitting DLT packet.");
            // for (int i = 0; i < msg_len; i++) {
            //     LOG_INF("  packet[%i]: %" PRIx8, i, dlt_recv_buf[i]);
            // }
            err = bt_nus_send(NULL, dlt_recv_buf, msg_len);
            LOG_INF("Data send - Result: %d\n", err);
            if (err < 0 && (err != -EAGAIN) && (err != -ENOTCONN)) {
                LOG_ERR("Unknown error. Aborting.");
                return;
            }
        }
        k_sleep(K_MSEC(5));
	}

}

/* Register the thread */
K_THREAD_DEFINE(dlt_nus_peripheral, DLT_NUS_STACKSIZE, dlt_nus_peripheral_thread,
                NULL, NULL, NULL, DLT_NUS_PRIORITY, 0, 0);
```

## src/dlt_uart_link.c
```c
#include <zephyr/kernel.h>
#include <zephyr/device.h>
#include <zephyr/drivers/uart.h>
#include <zephyr/logging/log.h>

#include "dlt_api.h"
#include "dlt_endpoints.h"

/* Thread parameters */
#define DLT_COMMS_STACKSIZE 1024
#define DLT_COMMS_PRIORITY  6

/* Timeout for UART DMA */
#define DLT_UART_RX_TIMEOUT (10 * USEC_PER_MSEC)

LOG_MODULE_REGISTER(dlt_uart_link, LOG_LEVEL_ERR);

/* UART DMA Semaphore for data reception */
K_SEM_DEFINE(dlt_rx_sem, 0, 1);

/* UART device reference */
#ifdef CONFIG_SHELL_BACKEND_RTT
static const struct device *dlt_uart =
    DEVICE_DT_GET(DT_CHOSEN(zephyr_shell_uart));
#else
static const struct device *dlt_uart = DEVICE_DT_GET(DT_ALIAS(dlt_uart));
#endif

/* UART callback prototype */
static void uart_cb(const struct device *dev, struct uart_event *evt,
                    void *user_data);

/* Intialise the DLT UART Link thread */
extern void dlt_uart_init()
{
    int ret = uart_callback_set(dlt_uart, uart_cb, NULL);
    if (ret) {
        LOG_ERR("DLT COMMS init failed.");
        return;
    }
}

/**
 * Thread function for DLT Communication.
 * 
 * @brief Periodically polls the DLT interface for packets to transmit and 
 *        forwards any received packets.
 */
void dlt_uart_thread(void)
{
    /* Initialise the UART peripheral and register Link with DLT driver */
    k_tid_t link_tid = k_current_get();
    dlt_uart_init();
    dlt_link_register(PI_UART, link_tid);

    /* Buffers */
    uint8_t dlt_recv_buf[DLT_MAX_PACKET_LEN] = {0};
    uint8_t uart_recv_buffer[DLT_MAX_PACKET_LEN] = {0};

    /* State variables */
    bool rx_on = false;
    int ret = 0;

    /* Sleep to let the main thread setup DLT */
    k_sleep(K_MSEC(100));

    while (1) {
        /* Poll DLT Interface for packets to transmit */
        uint8_t msg_len = dlt_poll(PI_UART, dlt_recv_buf, 50, K_MSEC(5));
        if (msg_len) {
            LOG_INF("DLT mail received.");

            /* Transmit the DLT packet via UART */
            LOG_INF("Transmitting DLT packet.");
            for (int i = 0; i < msg_len; i++) {
                LOG_INF("  packet[%i]: %" PRIx8, i, dlt_recv_buf[i]);
            }
            ret = uart_tx(dlt_uart, dlt_recv_buf, msg_len, SYS_FOREVER_US);
            if (ret) {
                LOG_ERR("DLT UART transmission failed.");
                break;
            }
        }

        /* Receive DLT messsages */ 
        if (!rx_on) {
            /* Start UART RX */
            ret = uart_rx_enable(dlt_uart, uart_recv_buffer,
                                 DLT_MAX_PACKET_LEN, DLT_UART_RX_TIMEOUT);
            if (ret) {
                LOG_ERR("DLT UART RX enable failed.");
                break;
            }
            rx_on = true;

        } else if (rx_on && (k_sem_take(&dlt_rx_sem, K_NO_WAIT) == 0)) {
            /* Submit the whole packet to DLT interface */
            LOG_INF("DLT UART packet received, %d bytes. Submitting.",
                    uart_recv_buffer[2] + DLT_PROTOCOL_BYTES);
            dlt_submit(PI_UART, uart_recv_buffer,
                       uart_recv_buffer[2] + DLT_PROTOCOL_BYTES, true);
            rx_on = false;
        }
        k_sleep(K_MSEC(5));
    }
}

/* Register the thread */
K_THREAD_DEFINE(dlt_comms, DLT_COMMS_STACKSIZE, dlt_uart_thread, NULL, NULL,
                NULL, DLT_COMMS_PRIORITY, 0, 0);

/*
 * UART Async API callback function
 *
 * @brief The callback function gives the dlt_rx semaphore when RX is complete.
 */
static void uart_cb(const struct device *dev, struct uart_event *evt,
                    void *user_data)
{
    switch (evt->type) {

    case UART_TX_DONE:

        break;

    case UART_RX_RDY:
        /* Disable UART after the RX is ready */
        uart_rx_disable(dlt_uart);
        break;

    case UART_RX_DISABLED:
        break;

    case UART_RX_STOPPED:
        LOG_ERR("DLT UART DMA ERROR.");
        break;

    case UART_RX_BUF_REQUEST:
        break;

    case UART_RX_BUF_RELEASED:
        LOG_INF("DLT UART DMA reception complete.");
        LOG_INF("Signalling thread.");
        k_sem_give(&dlt_rx_sem);
        break;

    default:
        break;
    }
}
```
